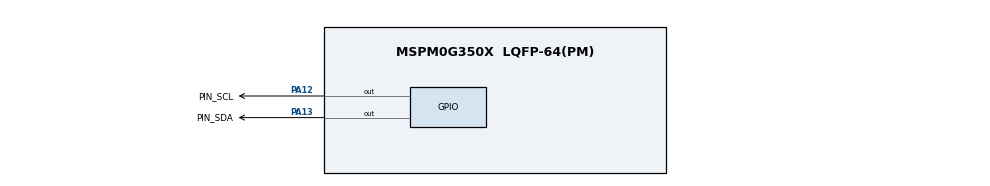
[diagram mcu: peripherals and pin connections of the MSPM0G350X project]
/**
 * @cliArgs --device "MSPM0G350X" --part "Default" --package "LQFP-64(PM)" --product "mspm0_sdk@2.03.00.08"
 * @versions {"tool":"1.21.1+3772"}
 */

/**
 * Import the modules used in this configuration.
 */
const GPIO   = scripting.addModule("/ti/driverlib/GPIO", {}, false);
const GPIO1  = GPIO.addInstance();
const SYSCTL = scripting.addModule("/ti/driverlib/SYSCTL");

/**
 * Write custom configuration values to the imported modules.
 */
GPIO1.$name                         = "GPIO_OLED";
GPIO1.port                          = "PORTA";
GPIO1.associatedPins.create(2);
GPIO1.associatedPins[0].$name       = "PIN_SCL";
GPIO1.associatedPins[0].assignedPin = "12";
GPIO1.associatedPins[0].pin.$assign = "PA12";
GPIO1.associatedPins[1].$name       = "PIN_SDA";
GPIO1.associatedPins[1].assignedPin = "13";
GPIO1.associatedPins[1].pin.$assign = "PA13";

const Board = scripting.addModule("/ti/driverlib/Board", {}, false);

SYSCTL.forceDefaultClkConfig = true;

/**
 * Pinmux solution for unlocked pins/peripherals. This ensures that minor changes to the automatic solver in a future
 * version of the tool will not impact the pinmux you originally saw.  These lines can be completely deleted in order to
 * re-solve from scratch.
 */
Board.peripheral.$suggestSolution          = "DEBUGSS";
Board.peripheral.swclkPin.$suggestSolution = "PA20";
Board.peripheral.swdioPin.$suggestSolution = "PA19";
SYSCTL.peripheral.$suggestSolution         = "SYSCTL";
